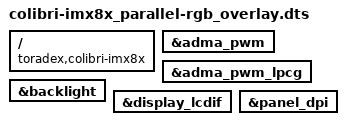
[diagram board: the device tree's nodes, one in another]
// Enable the parallel RGB interface on Colibri iMX8X

/dts-v1/;
/plugin/;
/ {
	compatible = "toradex,colibri-imx8x";
};

&adma_pwm {
        status = "okay";
};

&adma_pwm_lpcg {
	status = "okay";
};

&backlight {
        status = "okay";
};

&display_lcdif {
	status = "okay";
};

&panel_dpi {
	status = "okay";
};
